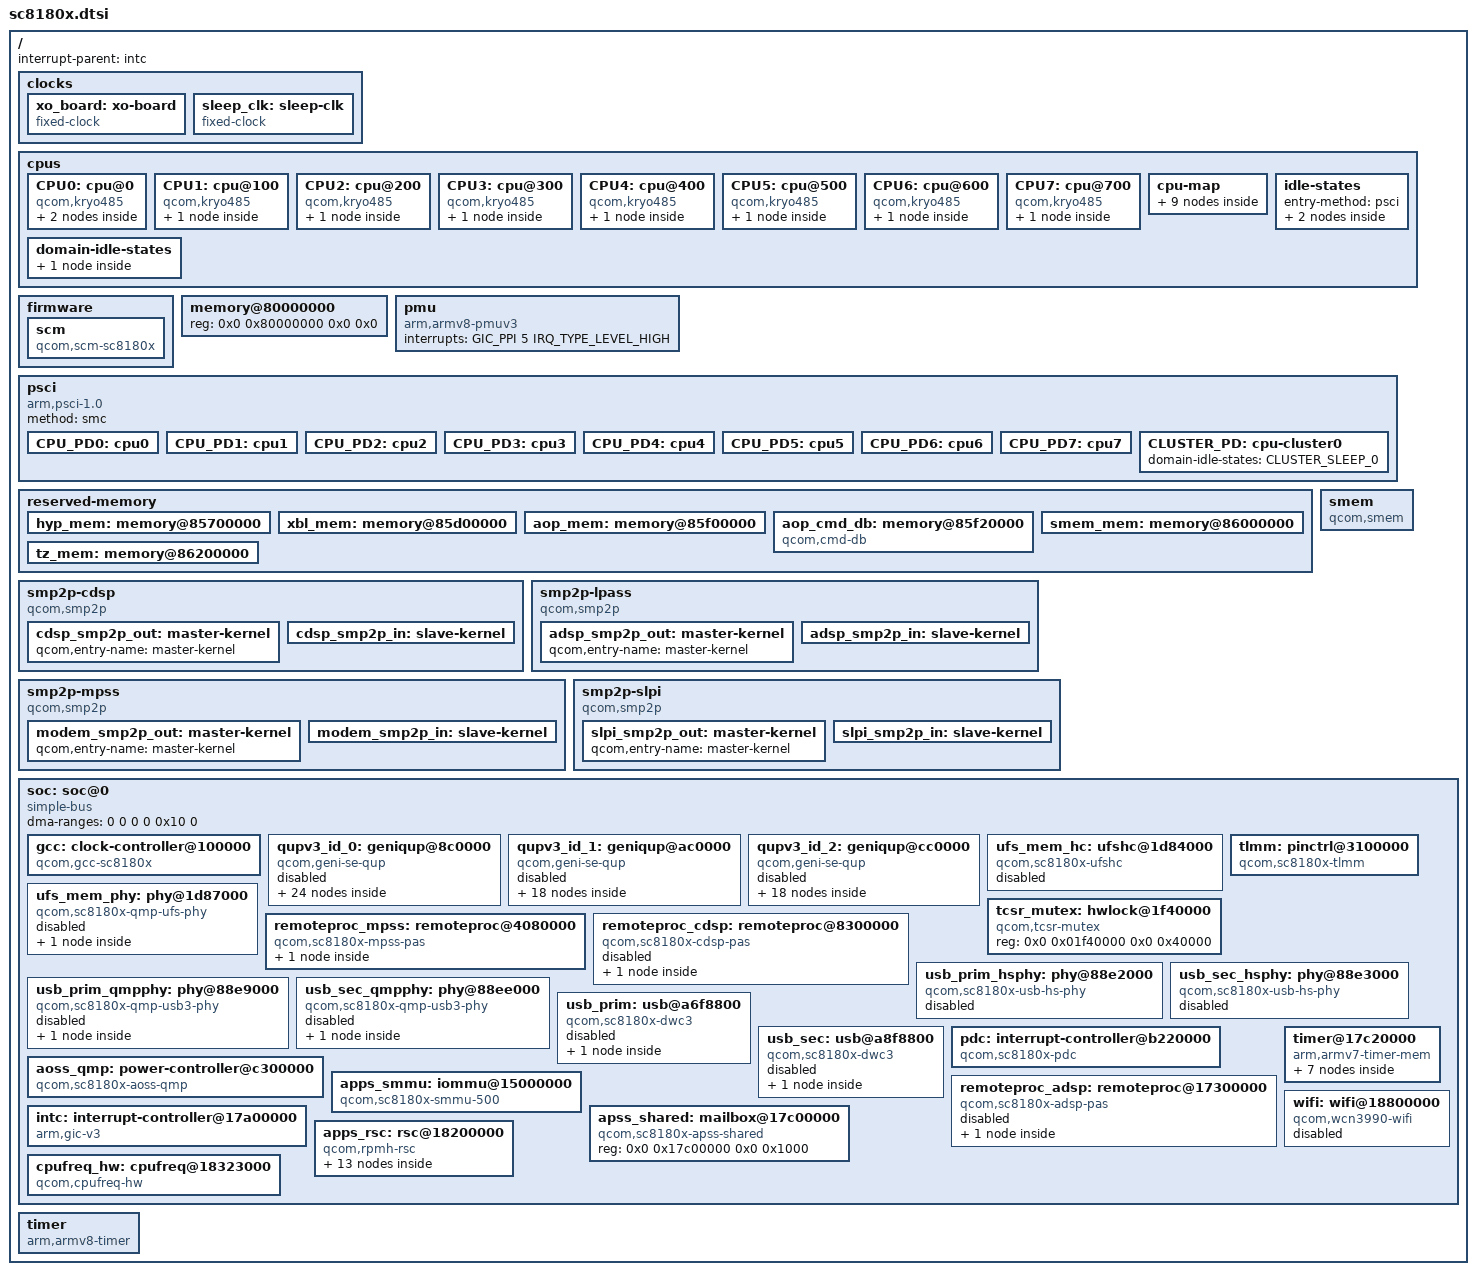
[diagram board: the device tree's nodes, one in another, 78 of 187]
// SPDX-License-Identifier: BSD-3-Clause
/*
 * Copyright (c) 2017-2019, The Linux Foundation. All rights reserved.
 * Copyright (c) 2020-2021, Linaro Limited
 */

#include <dt-bindings/interrupt-controller/arm-gic.h>
#include <dt-bindings/power/qcom-aoss-qmp.h>
#include <dt-bindings/power/qcom-rpmpd.h>
#include <dt-bindings/soc/qcom,rpmh-rsc.h>
#include <dt-bindings/clock/qcom,rpmh.h>
#include <dt-bindings/clock/qcom,gcc-sc8180x.h>
#include <dt-bindings/thermal/thermal.h>

/ {
	interrupt-parent = <&intc>;

	#address-cells = <2>;
	#size-cells = <2>;

	clocks {
		xo_board: xo-board {
			compatible = "fixed-clock";
			#clock-cells = <0>;
			clock-frequency = <38400000>;
			clock-output-names = "xo_board";
		};

		sleep_clk: sleep-clk {
			compatible = "fixed-clock";
			#clock-cells = <0>;
			clock-frequency = <32764>;
			clock-output-names = "sleep_clk";
		};
	};

	cpus {
		#address-cells = <2>;
		#size-cells = <0>;

		CPU0: cpu@0 {
			device_type = "cpu";
			compatible = "qcom,kryo485";
			reg = <0x0 0x0>;
			enable-method = "psci";
			capacity-dmips-mhz = <602>;
			next-level-cache = <&L2_0>;
			qcom,freq-domain = <&cpufreq_hw 0>;
			power-domains = <&CPU_PD0>;
			power-domain-names = "psci";
			#cooling-cells = <2>;
			L2_0: l2-cache {
				compatible = "cache";
				next-level-cache = <&L3_0>;
				L3_0: l3-cache {
				      compatible = "cache";
				};
			};
		};

		CPU1: cpu@100 {
			device_type = "cpu";
			compatible = "qcom,kryo485";
			reg = <0x0 0x100>;
			enable-method = "psci";
			capacity-dmips-mhz = <602>;
			next-level-cache = <&L2_100>;
			qcom,freq-domain = <&cpufreq_hw 0>;
			power-domains = <&CPU_PD1>;
			power-domain-names = "psci";
			#cooling-cells = <2>;
			L2_100: l2-cache {
				compatible = "cache";
				next-level-cache = <&L3_0>;
			};

		};

		CPU2: cpu@200 {
			device_type = "cpu";
			compatible = "qcom,kryo485";
			reg = <0x0 0x200>;
			enable-method = "psci";
			capacity-dmips-mhz = <602>;
			next-level-cache = <&L2_200>;
			qcom,freq-domain = <&cpufreq_hw 0>;
			power-domains = <&CPU_PD2>;
			power-domain-names = "psci";
			#cooling-cells = <2>;
			L2_200: l2-cache {
				compatible = "cache";
				next-level-cache = <&L3_0>;
			};
		};

		CPU3: cpu@300 {
			device_type = "cpu";
			compatible = "qcom,kryo485";
			reg = <0x0 0x300>;
			enable-method = "psci";
			capacity-dmips-mhz = <602>;
			next-level-cache = <&L2_300>;
			qcom,freq-domain = <&cpufreq_hw 0>;
			power-domains = <&CPU_PD3>;
			power-domain-names = "psci";
			#cooling-cells = <2>;
			L2_300: l2-cache {
				compatible = "cache";
				next-level-cache = <&L3_0>;
			};
		};

		CPU4: cpu@400 {
			device_type = "cpu";
			compatible = "qcom,kryo485";
			reg = <0x0 0x400>;
			enable-method = "psci";
			capacity-dmips-mhz = <1024>;
			next-level-cache = <&L2_400>;
			qcom,freq-domain = <&cpufreq_hw 1>;
			power-domains = <&CPU_PD4>;
			power-domain-names = "psci";
			#cooling-cells = <2>;
			L2_400: l2-cache {
				compatible = "cache";
				next-level-cache = <&L3_0>;
			};
		};

		CPU5: cpu@500 {
			device_type = "cpu";
			compatible = "qcom,kryo485";
			reg = <0x0 0x500>;
			enable-method = "psci";
			capacity-dmips-mhz = <1024>;
			next-level-cache = <&L2_500>;
			qcom,freq-domain = <&cpufreq_hw 1>;
			power-domains = <&CPU_PD5>;
			power-domain-names = "psci";
			#cooling-cells = <2>;
			L2_500: l2-cache {
				compatible = "cache";
				next-level-cache = <&L3_0>;
			};
		};

		CPU6: cpu@600 {
			device_type = "cpu";
			compatible = "qcom,kryo485";
			reg = <0x0 0x600>;
			enable-method = "psci";
			capacity-dmips-mhz = <1024>;
			next-level-cache = <&L2_600>;
			qcom,freq-domain = <&cpufreq_hw 1>;
			power-domains = <&CPU_PD6>;
			power-domain-names = "psci";
			#cooling-cells = <2>;
			L2_600: l2-cache {
				compatible = "cache";
				next-level-cache = <&L3_0>;
			};
		};

		CPU7: cpu@700 {
			device_type = "cpu";
			compatible = "qcom,kryo485";
			reg = <0x0 0x700>;
			enable-method = "psci";
			capacity-dmips-mhz = <1024>;
			next-level-cache = <&L2_700>;
			qcom,freq-domain = <&cpufreq_hw 1>;
			power-domains = <&CPU_PD7>;
			power-domain-names = "psci";
			#cooling-cells = <2>;
			L2_700: l2-cache {
				compatible = "cache";
				next-level-cache = <&L3_0>;
			};
		};

		cpu-map {
			cluster0 {
				core0 {
					cpu = <&CPU0>;
				};

				core1 {
					cpu = <&CPU1>;
				};

				core2 {
					cpu = <&CPU2>;
				};

				core3 {
					cpu = <&CPU3>;
				};

				core4 {
					cpu = <&CPU4>;
				};

				core5 {
					cpu = <&CPU5>;
				};

				core6 {
					cpu = <&CPU6>;
				};

				core7 {
					cpu = <&CPU7>;
				};
			};
		};

		idle-states {
			entry-method = "psci";

			LITTLE_CPU_SLEEP_0: cpu-sleep-0-0 {
				compatible = "arm,idle-state";
				idle-state-name = "little-rail-power-collapse";
				arm,psci-suspend-param = <0x40000004>;
				entry-latency-us = <355>;
				exit-latency-us = <909>;
				min-residency-us = <3934>;
				local-timer-stop;
			};

			BIG_CPU_SLEEP_0: cpu-sleep-1-0 {
				compatible = "arm,idle-state";
				idle-state-name = "big-rail-power-collapse";
				arm,psci-suspend-param = <0x40000004>;
				entry-latency-us = <241>;
				exit-latency-us = <1461>;
				min-residency-us = <4488>;
				local-timer-stop;
			};
		};

		domain-idle-states {
			CLUSTER_SLEEP_0: cluster-sleep-0 {
				compatible = "domain-idle-state";
				idle-state-name = "cluster-power-collapse";
				arm,psci-suspend-param = <0x4100c244>;
				entry-latency-us = <3263>;
				exit-latency-us = <6562>;
				min-residency-us = <9987>;
			};
		};
	};

	firmware {
		scm: scm {
			compatible = "qcom,scm-sc8180x", "qcom,scm";
		};
	};

	memory@80000000 {
		device_type = "memory";
		/* We expect the bootloader to fill in the size */
		reg = <0x0 0x80000000 0x0 0x0>;
	};

	pmu {
		compatible = "arm,armv8-pmuv3";
		interrupts = <GIC_PPI 5 IRQ_TYPE_LEVEL_HIGH>;
	};

	psci {
		compatible = "arm,psci-1.0";
		method = "smc";

		CPU_PD0: cpu0 {
			#power-domain-cells = <0>;
			power-domains = <&CLUSTER_PD>;
			domain-idle-states = <&LITTLE_CPU_SLEEP_0>;
		};

		CPU_PD1: cpu1 {
			#power-domain-cells = <0>;
			power-domains = <&CLUSTER_PD>;
			domain-idle-states = <&LITTLE_CPU_SLEEP_0>;
		};

		CPU_PD2: cpu2 {
			#power-domain-cells = <0>;
			power-domains = <&CLUSTER_PD>;
			domain-idle-states = <&LITTLE_CPU_SLEEP_0>;
		};

		CPU_PD3: cpu3 {
			#power-domain-cells = <0>;
			power-domains = <&CLUSTER_PD>;
			domain-idle-states = <&LITTLE_CPU_SLEEP_0>;
		};

		CPU_PD4: cpu4 {
			#power-domain-cells = <0>;
			power-domains = <&CLUSTER_PD>;
			domain-idle-states = <&BIG_CPU_SLEEP_0>;
		};

		CPU_PD5: cpu5 {
			#power-domain-cells = <0>;
			power-domains = <&CLUSTER_PD>;
			domain-idle-states = <&BIG_CPU_SLEEP_0>;
		};

		CPU_PD6: cpu6 {
			#power-domain-cells = <0>;
			power-domains = <&CLUSTER_PD>;
			domain-idle-states = <&BIG_CPU_SLEEP_0>;
		};

		CPU_PD7: cpu7 {
			#power-domain-cells = <0>;
			power-domains = <&CLUSTER_PD>;
			domain-idle-states = <&BIG_CPU_SLEEP_0>;
		};

		CLUSTER_PD: cpu-cluster0 {
			#power-domain-cells = <0>;
			domain-idle-states = <&CLUSTER_SLEEP_0>;
		};
	};

	reserved-memory {
		#address-cells = <2>;
		#size-cells = <2>;
		ranges;

		hyp_mem: memory@85700000 {
			reg = <0x0 0x85700000 0x0 0x600000>;
			no-map;
		};

		xbl_mem: memory@85d00000 {
			reg = <0x0 0x85d00000 0x0 0x140000>;
			no-map;
		};

		aop_mem: memory@85f00000 {
			reg = <0x0 0x85f00000 0x0 0x20000>;
			no-map;
		};

		aop_cmd_db: memory@85f20000 {
			compatible = "qcom,cmd-db";
			reg = <0x0 0x85f20000 0x0 0x20000>;
			no-map;
		};

		smem_mem: memory@86000000 {
			reg = <0x0 0x86000000 0x0 0x200000>;
			no-map;
		};

		tz_mem: memory@86200000 {
			reg = <0x0 0x86200000 0x0 0x3900000>;
			no-map;
		};
	};

	smem {
		compatible = "qcom,smem";
		memory-region = <&smem_mem>;
		hwlocks = <&tcsr_mutex 3>;
	};

	smp2p-cdsp {
		compatible = "qcom,smp2p";
		qcom,smem = <94>, <432>;

		interrupts = <GIC_SPI 576 IRQ_TYPE_EDGE_RISING>;

		mboxes = <&apss_shared 6>;

		qcom,local-pid = <0>;
		qcom,remote-pid = <5>;

		cdsp_smp2p_out: master-kernel {
			qcom,entry-name = "master-kernel";
			#qcom,smem-state-cells = <1>;
		};

		cdsp_smp2p_in: slave-kernel {
			qcom,entry-name = "slave-kernel";

			interrupt-controller;
			#interrupt-cells = <2>;
		};
	};

	smp2p-lpass {
		compatible = "qcom,smp2p";
		qcom,smem = <443>, <429>;

		interrupts = <GIC_SPI 158 IRQ_TYPE_EDGE_RISING>;

		mboxes = <&apss_shared 10>;

		qcom,local-pid = <0>;
		qcom,remote-pid = <2>;

		adsp_smp2p_out: master-kernel {
			qcom,entry-name = "master-kernel";
			#qcom,smem-state-cells = <1>;
		};

		adsp_smp2p_in: slave-kernel {
			qcom,entry-name = "slave-kernel";

			interrupt-controller;
			#interrupt-cells = <2>;
		};
	};

	smp2p-mpss {
		compatible = "qcom,smp2p";
		qcom,smem = <435>, <428>;

		interrupts = <GIC_SPI 451 IRQ_TYPE_EDGE_RISING>;

		mboxes = <&apss_shared 14>;

		qcom,local-pid = <0>;
		qcom,remote-pid = <1>;

		modem_smp2p_out: master-kernel {
			qcom,entry-name = "master-kernel";
			#qcom,smem-state-cells = <1>;
		};

		modem_smp2p_in: slave-kernel {
			qcom,entry-name = "slave-kernel";

			interrupt-controller;
			#interrupt-cells = <2>;
		};
	};

	smp2p-slpi {
		compatible = "qcom,smp2p";
		qcom,smem = <481>, <430>;

		interrupts = <GIC_SPI 172 IRQ_TYPE_EDGE_RISING>;

		mboxes = <&apss_shared 26>;

		qcom,local-pid = <0>;
		qcom,remote-pid = <3>;

		slpi_smp2p_out: master-kernel {
			qcom,entry-name = "master-kernel";
			#qcom,smem-state-cells = <1>;
		};

		slpi_smp2p_in: slave-kernel {
			qcom,entry-name = "slave-kernel";

			interrupt-controller;
			#interrupt-cells = <2>;
		};
	};

	soc: soc@0 {
		#address-cells = <2>;
		#size-cells = <2>;
		ranges = <0 0 0 0 0x10 0>;
		dma-ranges = <0 0 0 0 0x10 0>;
		compatible = "simple-bus";

		gcc: clock-controller@100000 {
			compatible = "qcom,gcc-sc8180x";
			reg = <0x0 0x00100000 0x0 0x1f0000>;
			#clock-cells = <1>;
			#reset-cells = <1>;
			#power-domain-cells = <1>;
			clock-names = "bi_tcxo",
				      "sleep_clk";
			clocks = <&rpmhcc RPMH_CXO_CLK>,
				 <&sleep_clk>;
		};

		qupv3_id_0: geniqup@8c0000 {
			compatible = "qcom,geni-se-qup";
			reg = <0 0x008c0000 0 0x6000>;
			clock-names = "m-ahb", "s-ahb";
			clocks = <&gcc GCC_QUPV3_WRAP_0_M_AHB_CLK>,
				 <&gcc GCC_QUPV3_WRAP_0_S_AHB_CLK>;
			#address-cells = <2>;
			#size-cells = <2>;
			ranges;
			iommus = <&apps_smmu 0x4c3 0>;
			status = "disabled";

			i2c0: i2c@880000 {
				compatible = "qcom,geni-i2c";
				reg = <0 0x00880000 0 0x4000>;
				clock-names = "se";
				clocks = <&gcc GCC_QUPV3_WRAP0_S0_CLK>;
				interrupts = <GIC_SPI 601 IRQ_TYPE_LEVEL_HIGH>;
				#address-cells = <1>;
				#size-cells = <0>;
				status = "disabled";
			};

			spi0: spi@880000 {
				compatible = "qcom,geni-spi";
				reg = <0 0x00880000 0 0x4000>;
				clock-names = "se";
				clocks = <&gcc GCC_QUPV3_WRAP0_S0_CLK>;
				interrupts = <GIC_SPI 601 IRQ_TYPE_LEVEL_HIGH>;
				#address-cells = <1>;
				#size-cells = <0>;
				status = "disabled";
			};

			uart0: serial@880000 {
				compatible = "qcom,geni-uart";
				reg = <0 0x00880000 0 0x4000>;
				clock-names = "se";
				clocks = <&gcc GCC_QUPV3_WRAP0_S0_CLK>;
				interrupts = <GIC_SPI 601 IRQ_TYPE_LEVEL_HIGH>;
				status = "disabled";
			};

			i2c1: i2c@884000 {
				compatible = "qcom,geni-i2c";
				reg = <0 0x00884000 0 0x4000>;
				clock-names = "se";
				clocks = <&gcc GCC_QUPV3_WRAP0_S1_CLK>;
				interrupts = <GIC_SPI 602 IRQ_TYPE_LEVEL_HIGH>;
				#address-cells = <1>;
				#size-cells = <0>;
				status = "disabled";
			};

			spi1: spi@884000 {
				compatible = "qcom,geni-spi";
				reg = <0 0x00884000 0 0x4000>;
				clock-names = "se";
				clocks = <&gcc GCC_QUPV3_WRAP0_S1_CLK>;
				interrupts = <GIC_SPI 602 IRQ_TYPE_LEVEL_HIGH>;
				#address-cells = <1>;
				#size-cells = <0>;
				status = "disabled";
			};

			uart1: serial@884000 {
				compatible = "qcom,geni-uart";
				reg = <0 0x00884000 0 0x4000>;
				clock-names = "se";
				clocks = <&gcc GCC_QUPV3_WRAP0_S1_CLK>;
				interrupts = <GIC_SPI 602 IRQ_TYPE_LEVEL_HIGH>;
				status = "disabled";
			};

			i2c2: i2c@888000 {
				compatible = "qcom,geni-i2c";
				reg = <0 0x00888000 0 0x4000>;
				clock-names = "se";
				clocks = <&gcc GCC_QUPV3_WRAP0_S2_CLK>;
				interrupts = <GIC_SPI 603 IRQ_TYPE_LEVEL_HIGH>;
				#address-cells = <1>;
				#size-cells = <0>;
				status = "disabled";
			};

			spi2: spi@888000 {
				compatible = "qcom,geni-spi";
				reg = <0 0x00888000 0 0x4000>;
				clock-names = "se";
				clocks = <&gcc GCC_QUPV3_WRAP0_S2_CLK>;
				interrupts = <GIC_SPI 603 IRQ_TYPE_LEVEL_HIGH>;
				#address-cells = <1>;
				#size-cells = <0>;
				status = "disabled";
			};

			uart2: serial@888000 {
				compatible = "qcom,geni-uart";
				reg = <0 0x00888000 0 0x4000>;
				clock-names = "se";
				clocks = <&gcc GCC_QUPV3_WRAP0_S2_CLK>;
				interrupts = <GIC_SPI 603 IRQ_TYPE_LEVEL_HIGH>;
				status = "disabled";
			};

			i2c3: i2c@88c000 {
				compatible = "qcom,geni-i2c";
				reg = <0 0x0088c000 0 0x4000>;
				clock-names = "se";
				clocks = <&gcc GCC_QUPV3_WRAP0_S3_CLK>;
				interrupts = <GIC_SPI 604 IRQ_TYPE_LEVEL_HIGH>;
				#address-cells = <1>;
				#size-cells = <0>;
				status = "disabled";
			};

			spi3: spi@88c000 {
				compatible = "qcom,geni-spi";
				reg = <0 0x0088c000 0 0x4000>;
				clock-names = "se";
				clocks = <&gcc GCC_QUPV3_WRAP0_S3_CLK>;
				interrupts = <GIC_SPI 604 IRQ_TYPE_LEVEL_HIGH>;
				#address-cells = <1>;
				#size-cells = <0>;
				status = "disabled";
			};

			uart3: serial@88c000 {
				compatible = "qcom,geni-uart";
				reg = <0 0x0088c000 0 0x4000>;
				clock-names = "se";
				clocks = <&gcc GCC_QUPV3_WRAP0_S3_CLK>;
				interrupts = <GIC_SPI 604 IRQ_TYPE_LEVEL_HIGH>;
				status = "disabled";
			};

			i2c4: i2c@890000 {
				compatible = "qcom,geni-i2c";
				reg = <0 0x00890000 0 0x4000>;
				clock-names = "se";
				clocks = <&gcc GCC_QUPV3_WRAP0_S4_CLK>;
				interrupts = <GIC_SPI 605 IRQ_TYPE_LEVEL_HIGH>;
				#address-cells = <1>;
				#size-cells = <0>;
				status = "disabled";
			};

			spi4: spi@890000 {
				compatible = "qcom,geni-spi";
				reg = <0 0x00890000 0 0x4000>;
				clock-names = "se";
				clocks = <&gcc GCC_QUPV3_WRAP0_S4_CLK>;
				interrupts = <GIC_SPI 605 IRQ_TYPE_LEVEL_HIGH>;
				#address-cells = <1>;
				#size-cells = <0>;
				status = "disabled";
			};

			uart4: serial@890000 {
				compatible = "qcom,geni-uart";
				reg = <0 0x00890000 0 0x4000>;
				clock-names = "se";
				clocks = <&gcc GCC_QUPV3_WRAP0_S4_CLK>;
				interrupts = <GIC_SPI 605 IRQ_TYPE_LEVEL_HIGH>;
				status = "disabled";
			};

			i2c5: i2c@894000 {
				compatible = "qcom,geni-i2c";
				reg = <0 0x00894000 0 0x4000>;
				clock-names = "se";
				clocks = <&gcc GCC_QUPV3_WRAP0_S5_CLK>;
				interrupts = <GIC_SPI 606 IRQ_TYPE_LEVEL_HIGH>;
				#address-cells = <1>;
				#size-cells = <0>;
				status = "disabled";
			};

			spi5: spi@894000 {
				compatible = "qcom,geni-spi";
				reg = <0 0x00894000 0 0x4000>;
				clock-names = "se";
				clocks = <&gcc GCC_QUPV3_WRAP0_S5_CLK>;
				interrupts = <GIC_SPI 606 IRQ_TYPE_LEVEL_HIGH>;
				#address-cells = <1>;
				#size-cells = <0>;
				status = "disabled";
			};

			uart5: serial@894000 {
				compatible = "qcom,geni-uart";
				reg = <0 0x00894000 0 0x4000>;
				clock-names = "se";
				clocks = <&gcc GCC_QUPV3_WRAP0_S5_CLK>;
				interrupts = <GIC_SPI 606 IRQ_TYPE_LEVEL_HIGH>;
				status = "disabled";
			};

			i2c6: i2c@898000 {
				compatible = "qcom,geni-i2c";
				reg = <0 0x00898000 0 0x4000>;
				clock-names = "se";
				clocks = <&gcc GCC_QUPV3_WRAP0_S6_CLK>;
				interrupts = <GIC_SPI 607 IRQ_TYPE_LEVEL_HIGH>;
				#address-cells = <1>;
				#size-cells = <0>;
				status = "disabled";
			};

			spi6: spi@898000 {
				compatible = "qcom,geni-spi";
				reg = <0 0x00898000 0 0x4000>;
				clock-names = "se";
				clocks = <&gcc GCC_QUPV3_WRAP0_S6_CLK>;
				interrupts = <GIC_SPI 607 IRQ_TYPE_LEVEL_HIGH>;
				#address-cells = <1>;
				#size-cells = <0>;
				status = "disabled";
			};

			uart6: serial@898000 {
				compatible = "qcom,geni-uart";
				reg = <0 0x00898000 0 0x4000>;
				clock-names = "se";
				clocks = <&gcc GCC_QUPV3_WRAP0_S6_CLK>;
				interrupts = <GIC_SPI 607 IRQ_TYPE_LEVEL_HIGH>;
				status = "disabled";
			};

			i2c7: i2c@89c000 {
				compatible = "qcom,geni-i2c";
				reg = <0 0x0089c000 0 0x4000>;
				clock-names = "se";
				clocks = <&gcc GCC_QUPV3_WRAP0_S7_CLK>;
				interrupts = <GIC_SPI 608 IRQ_TYPE_LEVEL_HIGH>;
				#address-cells = <1>;
				#size-cells = <0>;
				status = "disabled";
			};

			spi7: spi@89c000 {
				compatible = "qcom,geni-spi";
				reg = <0 0x0089c000 0 0x4000>;
				clock-names = "se";
				clocks = <&gcc GCC_QUPV3_WRAP0_S7_CLK>;
				interrupts = <GIC_SPI 608 IRQ_TYPE_LEVEL_HIGH>;
				#address-cells = <1>;
				#size-cells = <0>;
				status = "disabled";
			};

			uart7: serial@89c000 {
				compatible = "qcom,geni-uart";
				reg = <0 0x0089c000 0 0x4000>;
				clock-names = "se";
				clocks = <&gcc GCC_QUPV3_WRAP0_S7_CLK>;
				interrupts = <GIC_SPI 608 IRQ_TYPE_LEVEL_HIGH>;
				status = "disabled";
			};
		};

		qupv3_id_1: geniqup@ac0000 {
			compatible = "qcom,geni-se-qup";
			reg = <0x0 0x00ac0000 0x0 0x6000>;
			clock-names = "m-ahb", "s-ahb";
			clocks = <&gcc GCC_QUPV3_WRAP_1_M_AHB_CLK>,
				 <&gcc GCC_QUPV3_WRAP_1_S_AHB_CLK>;
			#address-cells = <2>;
			#size-cells = <2>;
			ranges;
			iommus = <&apps_smmu 0x603 0>;
			status = "disabled";

			i2c8: i2c@a80000 {
				compatible = "qcom,geni-i2c";
				reg = <0 0x00a80000 0 0x4000>;
				clock-names = "se";
				clocks = <&gcc GCC_QUPV3_WRAP1_S0_CLK>;
				interrupts = <GIC_SPI 353 IRQ_TYPE_LEVEL_HIGH>;
				#address-cells = <1>;
				#size-cells = <0>;
				status = "disabled";
			};

			spi8: spi@a80000 {
				compatible = "qcom,geni-spi";
				reg = <0 0x00a80000 0 0x4000>;
				clock-names = "se";
				clocks = <&gcc GCC_QUPV3_WRAP1_S0_CLK>;
				interrupts = <GIC_SPI 353 IRQ_TYPE_LEVEL_HIGH>;
				#address-cells = <1>;
				#size-cells = <0>;
				status = "disabled";
			};

			uart8: serial@a80000 {
				compatible = "qcom,geni-uart";
				reg = <0 0x00a80000 0 0x4000>;
				clock-names = "se";
				clocks = <&gcc GCC_QUPV3_WRAP1_S0_CLK>;
				interrupts = <GIC_SPI 353 IRQ_TYPE_LEVEL_HIGH>;
				status = "disabled";
			};

			i2c9: i2c@a84000 {
				compatible = "qcom,geni-i2c";
				reg = <0 0x00a84000 0 0x4000>;
				clock-names = "se";
				clocks = <&gcc GCC_QUPV3_WRAP1_S1_CLK>;
				interrupts = <GIC_SPI 354 IRQ_TYPE_LEVEL_HIGH>;
				#address-cells = <1>;
				#size-cells = <0>;
				status = "disabled";
			};

			spi9: spi@a84000 {
				compatible = "qcom,geni-spi";
				reg = <0 0x00a84000 0 0x4000>;
				clock-names = "se";
				clocks = <&gcc GCC_QUPV3_WRAP1_S1_CLK>;
				interrupts = <GIC_SPI 354 IRQ_TYPE_LEVEL_HIGH>;
				#address-cells = <1>;
				#size-cells = <0>;
				status = "disabled";
			};

			uart9: serial@a84000 {
				compatible = "qcom,geni-debug-uart";
				reg = <0 0x00a84000 0 0x4000>;
				clock-names = "se";
				clocks = <&gcc GCC_QUPV3_WRAP1_S1_CLK>;
				interrupts = <GIC_SPI 354 IRQ_TYPE_LEVEL_HIGH>;
				status = "disabled";
			};

			i2c10: i2c@a88000 {
				compatible = "qcom,geni-i2c";
				reg = <0 0x00a88000 0 0x4000>;
				clock-names = "se";
				clocks = <&gcc GCC_QUPV3_WRAP1_S2_CLK>;
				interrupts = <GIC_SPI 355 IRQ_TYPE_LEVEL_HIGH>;
				#address-cells = <1>;
				#size-cells = <0>;
				status = "disabled";
			};

			spi10: spi@a88000 {
				compatible = "qcom,geni-spi";
				reg = <0 0x00a88000 0 0x4000>;
				clock-names = "se";
				clocks = <&gcc GCC_QUPV3_WRAP1_S2_CLK>;
				interrupts = <GIC_SPI 355 IRQ_TYPE_LEVEL_HIGH>;
				#address-cells = <1>;
				#size-cells = <0>;
				status = "disabled";
			};

			uart10: serial@a88000 {
				compatible = "qcom,geni-uart";
				reg = <0 0x00a88000 0 0x4000>;
				clock-names = "se";
				clocks = <&gcc GCC_QUPV3_WRAP1_S2_CLK>;
				interrupts = <GIC_SPI 355 IRQ_TYPE_LEVEL_HIGH>;
				status = "disabled";
			};

			i2c11: i2c@a8c000 {
				compatible = "qcom,geni-i2c";
				reg = <0 0x00a8c000 0 0x4000>;
				clock-names = "se";
				clocks = <&gcc GCC_QUPV3_WRAP1_S3_CLK>;
				interrupts = <GIC_SPI 356 IRQ_TYPE_LEVEL_HIGH>;
				#address-cells = <1>;
				#size-cells = <0>;
				status = "disabled";
			};

			spi11: spi@a8c000 {
				compatible = "qcom,geni-spi";
				reg = <0 0x00a8c000 0 0x4000>;
				clock-names = "se";
				clocks = <&gcc GCC_QUPV3_WRAP1_S3_CLK>;
				interrupts = <GIC_SPI 356 IRQ_TYPE_LEVEL_HIGH>;
				#address-cells = <1>;
				#size-cells = <0>;
				status = "disabled";
			};

			uart11: serial@a8c000 {
				compatible = "qcom,geni-uart";
				reg = <0 0x00a8c000 0 0x4000>;
				clock-names = "se";
				clocks = <&gcc GCC_QUPV3_WRAP1_S3_CLK>;
				interrupts = <GIC_SPI 356 IRQ_TYPE_LEVEL_HIGH>;
				status = "disabled";
			};

			i2c12: i2c@a90000 {
				compatible = "qcom,geni-i2c";
				reg = <0 0x00a90000 0 0x4000>;
				clock-names = "se";
				clocks = <&gcc GCC_QUPV3_WRAP1_S4_CLK>;
				interrupts = <GIC_SPI 357 IRQ_TYPE_LEVEL_HIGH>;
				#address-cells = <1>;
				#size-cells = <0>;
				status = "disabled";
			};

			spi12: spi@a90000 {
				compatible = "qcom,geni-spi";
				reg = <0 0x00a90000 0 0x4000>;
				clock-names = "se";
				clocks = <&gcc GCC_QUPV3_WRAP1_S4_CLK>;
				interrupts = <GIC_SPI 357 IRQ_TYPE_LEVEL_HIGH>;
				#address-cells = <1>;
				#size-cells = <0>;
				status = "disabled";
			};

			uart12: serial@a90000 {
				compatible = "qcom,geni-uart";
				reg = <0 0x00a90000 0 0x4000>;
				clock-names = "se";
				clocks = <&gcc GCC_QUPV3_WRAP1_S4_CLK>;
				interrupts = <GIC_SPI 357 IRQ_TYPE_LEVEL_HIGH>;
				status = "disabled";
			};

			i2c16: i2c@a94000 {
				compatible = "qcom,geni-i2c";
				reg = <0 0x00a94000 0 0x4000>;
				clock-names = "se";
				clocks = <&gcc GCC_QUPV3_WRAP1_S5_CLK>;
				interrupts = <GIC_SPI 358 IRQ_TYPE_LEVEL_HIGH>;
				#address-cells = <1>;
				#size-cells = <0>;
				status = "disabled";
			};

			spi16: spi@a94000 {
				compatible = "qcom,geni-spi";
				reg = <0 0x00a94000 0 0x4000>;
				clock-names = "se";
				clocks = <&gcc GCC_QUPV3_WRAP1_S5_CLK>;
				interrupts = <GIC_SPI 358 IRQ_TYPE_LEVEL_HIGH>;
				#address-cells = <1>;
				#size-cells = <0>;
				status = "disabled";
			};

			uart16: serial@a94000 {
				compatible = "qcom,geni-uart";
				reg = <0 0x00a94000 0 0x4000>;
				clock-names = "se";
				clocks = <&gcc GCC_QUPV3_WRAP1_S5_CLK>;
				interrupts = <GIC_SPI 358 IRQ_TYPE_LEVEL_HIGH>;
				status = "disabled";
			};
		};

		qupv3_id_2: geniqup@cc0000 {
			compatible = "qcom,geni-se-qup";
			reg = <0x0 0x00cc0000 0x0 0x6000>;
			clock-names = "m-ahb", "s-ahb";
			clocks = <&gcc GCC_QUPV3_WRAP_2_M_AHB_CLK>,
				 <&gcc GCC_QUPV3_WRAP_2_S_AHB_CLK>;
			#address-cells = <2>;
			#size-cells = <2>;
			ranges;
			iommus = <&apps_smmu 0x7a3 0>;
			status = "disabled";

			i2c17: i2c@c80000 {
				compatible = "qcom,geni-i2c";
				reg = <0 0x00c80000 0 0x4000>;
				clock-names = "se";
				clocks = <&gcc GCC_QUPV3_WRAP2_S0_CLK>;
				interrupts = <GIC_SPI 373 IRQ_TYPE_LEVEL_HIGH>;
				#address-cells = <1>;
				#size-cells = <0>;
				status = "disabled";
			};

			spi17: spi@c80000 {
				compatible = "qcom,geni-spi";
				reg = <0 0x00c80000 0 0x4000>;
				clock-names = "se";
				clocks = <&gcc GCC_QUPV3_WRAP2_S0_CLK>;
				interrupts = <GIC_SPI 373 IRQ_TYPE_LEVEL_HIGH>;
				#address-cells = <1>;
				#size-cells = <0>;
				status = "disabled";
			};

			uart17: serial@c80000 {
				compatible = "qcom,geni-uart";
				reg = <0 0x00c80000 0 0x4000>;
				clock-names = "se";
				clocks = <&gcc GCC_QUPV3_WRAP2_S0_CLK>;
				interrupts = <GIC_SPI 373 IRQ_TYPE_LEVEL_HIGH>;
				status = "disabled";
			};

			i2c18: i2c@c84000 {
				compatible = "qcom,geni-i2c";
				reg = <0 0x00c84000 0 0x4000>;
				clock-names = "se";
				clocks = <&gcc GCC_QUPV3_WRAP2_S1_CLK>;
				interrupts = <GIC_SPI 583 IRQ_TYPE_LEVEL_HIGH>;
				#address-cells = <1>;
				#size-cells = <0>;
				status = "disabled";
			};

			spi18: spi@c84000 {
				compatible = "qcom,geni-spi";
				reg = <0 0x00c84000 0 0x4000>;
				clock-names = "se";
				clocks = <&gcc GCC_QUPV3_WRAP2_S1_CLK>;
				interrupts = <GIC_SPI 583 IRQ_TYPE_LEVEL_HIGH>;
				#address-cells = <1>;
				#size-cells = <0>;
				status = "disabled";
			};

			uart18: serial@c84000 {
				compatible = "qcom,geni-uart";
				reg = <0 0x00c84000 0 0x4000>;
				clock-names = "se";
				clocks = <&gcc GCC_QUPV3_WRAP2_S1_CLK>;
				interrupts = <GIC_SPI 583 IRQ_TYPE_LEVEL_HIGH>;
				status = "disabled";
			};

			i2c19: i2c@c88000 {
				compatible = "qcom,geni-i2c";
				reg = <0 0x00c88000 0 0x4000>;
				clock-names = "se";
				clocks = <&gcc GCC_QUPV3_WRAP2_S2_CLK>;
				interrupts = <GIC_SPI 584 IRQ_TYPE_LEVEL_HIGH>;
				#address-cells = <1>;
				#size-cells = <0>;
				status = "disabled";
			};

			spi19: spi@c88000 {
				compatible = "qcom,geni-spi";
				reg = <0 0x00c88000 0 0x4000>;
				clock-names = "se";
				clocks = <&gcc GCC_QUPV3_WRAP2_S2_CLK>;
				interrupts = <GIC_SPI 584 IRQ_TYPE_LEVEL_HIGH>;
				#address-cells = <1>;
				#size-cells = <0>;
				status = "disabled";
			};

			uart19: serial@c88000 {
				compatible = "qcom,geni-uart";
				reg = <0 0x00c88000 0 0x4000>;
				clock-names = "se";
				clocks = <&gcc GCC_QUPV3_WRAP2_S2_CLK>;
				interrupts = <GIC_SPI 584 IRQ_TYPE_LEVEL_HIGH>;
				status = "disabled";
			};

			i2c13: i2c@c8c000 {
				compatible = "qcom,geni-i2c";
				reg = <0 0x00c8c000 0 0x4000>;
				clock-names = "se";
				clocks = <&gcc GCC_QUPV3_WRAP2_S3_CLK>;
				interrupts = <GIC_SPI 585 IRQ_TYPE_LEVEL_HIGH>;
				#address-cells = <1>;
				#size-cells = <0>;
				status = "disabled";
			};

			spi13: spi@c8c000 {
				compatible = "qcom,geni-spi";
				reg = <0 0x00c8c000 0 0x4000>;
				clock-names = "se";
				clocks = <&gcc GCC_QUPV3_WRAP2_S3_CLK>;
				interrupts = <GIC_SPI 585 IRQ_TYPE_LEVEL_HIGH>;
				#address-cells = <1>;
				#size-cells = <0>;
				status = "disabled";
			};

			uart13: serial@c8c000 {
				compatible = "qcom,geni-uart";
				reg = <0 0x00c8c000 0 0x4000>;
				clock-names = "se";
				clocks = <&gcc GCC_QUPV3_WRAP2_S3_CLK>;
				interrupts = <GIC_SPI 585 IRQ_TYPE_LEVEL_HIGH>;
				status = "disabled";
			};

			i2c14: i2c@c90000 {
				compatible = "qcom,geni-i2c";
				reg = <0 0x00c90000 0 0x4000>;
				clock-names = "se";
				clocks = <&gcc GCC_QUPV3_WRAP2_S4_CLK>;
				interrupts = <GIC_SPI 586 IRQ_TYPE_LEVEL_HIGH>;
				#address-cells = <1>;
				#size-cells = <0>;
				status = "disabled";
			};

			spi14: spi@c90000 {
				compatible = "qcom,geni-spi";
				reg = <0 0x00c90000 0 0x4000>;
				clock-names = "se";
				clocks = <&gcc GCC_QUPV3_WRAP2_S4_CLK>;
				interrupts = <GIC_SPI 586 IRQ_TYPE_LEVEL_HIGH>;
				#address-cells = <1>;
				#size-cells = <0>;
				status = "disabled";
			};

			uart14: serial@c90000 {
				compatible = "qcom,geni-uart";
				reg = <0 0x00c90000 0 0x4000>;
				clock-names = "se";
				clocks = <&gcc GCC_QUPV3_WRAP2_S4_CLK>;
				interrupts = <GIC_SPI 586 IRQ_TYPE_LEVEL_HIGH>;
				status = "disabled";
			};

			i2c15: i2c@c94000 {
				compatible = "qcom,geni-i2c";
				reg = <0 0x00c94000 0 0x4000>;
				clock-names = "se";
				clocks = <&gcc GCC_QUPV3_WRAP2_S5_CLK>;
				interrupts = <GIC_SPI 587 IRQ_TYPE_LEVEL_HIGH>;
				#address-cells = <1>;
				#size-cells = <0>;
				status = "disabled";
			};

			spi15: spi@c94000 {
				compatible = "qcom,geni-spi";
				reg = <0 0x00c94000 0 0x4000>;
				clock-names = "se";
				clocks = <&gcc GCC_QUPV3_WRAP2_S5_CLK>;
				interrupts = <GIC_SPI 587 IRQ_TYPE_LEVEL_HIGH>;
				#address-cells = <1>;
				#size-cells = <0>;
				status = "disabled";
			};

			uart15: serial@c94000 {
				compatible = "qcom,geni-uart";
				reg = <0 0x00c94000 0 0x4000>;
				clock-names = "se";
				clocks = <&gcc GCC_QUPV3_WRAP2_S5_CLK>;
				interrupts = <GIC_SPI 587 IRQ_TYPE_LEVEL_HIGH>;
				status = "disabled";
			};
		};

		ufs_mem_hc: ufshc@1d84000 {
			compatible = "qcom,sc8180x-ufshc", "qcom,ufshc",
				     "jedec,ufs-2.0";
			reg = <0 0x01d84000 0 0x2500>;
			interrupts = <GIC_SPI 265 IRQ_TYPE_LEVEL_HIGH>;
			phys = <&ufs_mem_phy_lanes>;
			phy-names = "ufsphy";
			lanes-per-direction = <2>;
			#reset-cells = <1>;
			resets = <&gcc GCC_UFS_PHY_BCR>;
			reset-names = "rst";

			iommus = <&apps_smmu 0x300 0>;

			clock-names =
				"core_clk",
				"bus_aggr_clk",
				"iface_clk",
				"core_clk_unipro",
				"ref_clk",
				"tx_lane0_sync_clk",
				"rx_lane0_sync_clk",
				"rx_lane1_sync_clk";
			clocks =
				<&gcc GCC_UFS_PHY_AXI_CLK>,
				<&gcc GCC_AGGRE_UFS_PHY_AXI_CLK>,
				<&gcc GCC_UFS_PHY_AHB_CLK>,
				<&gcc GCC_UFS_PHY_UNIPRO_CORE_CLK>,
				<&rpmhcc RPMH_CXO_CLK>,
				<&gcc GCC_UFS_PHY_TX_SYMBOL_0_CLK>,
				<&gcc GCC_UFS_PHY_RX_SYMBOL_0_CLK>,
				<&gcc GCC_UFS_PHY_RX_SYMBOL_1_CLK>;
			freq-table-hz =
				<37500000 300000000>,
				<0 0>,
				<0 0>,
				<37500000 300000000>,
				<0 0>,
				<0 0>,
				<0 0>,
				<0 0>;

			status = "disabled";
		};

		ufs_mem_phy: phy@1d87000 {
			compatible = "qcom,sc8180x-qmp-ufs-phy";
			reg = <0 0x01d87000 0 0x1c0>;
			#address-cells = <2>;
			#size-cells = <2>;
			ranges;
			clock-names = "ref",
				      "ref_aux";
			clocks = <&rpmhcc RPMH_CXO_CLK>,
				 <&gcc GCC_UFS_PHY_PHY_AUX_CLK>;

			resets = <&ufs_mem_hc 0>;
			reset-names = "ufsphy";
			status = "disabled";

			ufs_mem_phy_lanes: lanes@1d87400 {
				reg = <0 0x01d87400 0 0x108>,
				      <0 0x01d87600 0 0x1e0>,
				      <0 0x01d87c00 0 0x1dc>,
				      <0 0x01d87800 0 0x108>,
				      <0 0x01d87a00 0 0x1e0>;
				#phy-cells = <0>;
			};
		};

		tcsr_mutex: hwlock@1f40000 {
			compatible = "qcom,tcsr-mutex";
			reg = <0x0 0x01f40000 0x0 0x40000>;
			#hwlock-cells = <1>;
		};

		tlmm: pinctrl@3100000 {
			compatible = "qcom,sc8180x-tlmm";
			reg = <0 0x03100000 0 0x300000>,
			      <0 0x03500000 0 0x700000>,
			      <0 0x03d00000 0 0x300000>;
			reg-names = "west", "east", "south";
			interrupts = <GIC_SPI 208 IRQ_TYPE_LEVEL_HIGH>;
			gpio-controller;
			#gpio-cells = <2>;
			interrupt-controller;
			#interrupt-cells = <2>;
			gpio-ranges = <&tlmm 0 0 190>;
			wakeup-parent = <&pdc>;
		};

		remoteproc_mpss: remoteproc@4080000 {
			compatible = "qcom,sc8180x-mpss-pas";
			reg = <0x0 0x04080000 0x0 0x4040>;

			interrupts-extended = <&intc GIC_SPI 266 IRQ_TYPE_EDGE_RISING>,
					      <&modem_smp2p_in 0 IRQ_TYPE_EDGE_RISING>,
					      <&modem_smp2p_in 1 IRQ_TYPE_EDGE_RISING>,
					      <&modem_smp2p_in 2 IRQ_TYPE_EDGE_RISING>,
					      <&modem_smp2p_in 3 IRQ_TYPE_EDGE_RISING>,
					      <&modem_smp2p_in 7 IRQ_TYPE_EDGE_RISING>;
			interrupt-names = "wdog", "fatal", "ready", "handover",
					  "stop-ack", "shutdown-ack";

			clocks = <&rpmhcc RPMH_CXO_CLK>;
			clock-names = "xo";

			power-domains = <&aoss_qmp AOSS_QMP_LS_MODEM>,
					<&rpmhpd SC8180X_CX>,
					<&rpmhpd SC8180X_MSS>;
			power-domain-names = "load_state", "cx", "mss";

			qcom,smem-states = <&modem_smp2p_out 0>;
			qcom,smem-state-names = "stop";

			glink-edge {
				interrupts = <GIC_SPI 449 IRQ_TYPE_EDGE_RISING>;
				label = "modem";
				qcom,remote-pid = <1>;
				mboxes = <&apss_shared 12>;
			};
		};

		remoteproc_cdsp: remoteproc@8300000 {
			compatible = "qcom,sc8180x-cdsp-pas";
			reg = <0x0 0x08300000 0x0 0x4040>;

			interrupts-extended = <&intc GIC_SPI 578 IRQ_TYPE_EDGE_RISING>,
					      <&cdsp_smp2p_in 0 IRQ_TYPE_EDGE_RISING>,
					      <&cdsp_smp2p_in 1 IRQ_TYPE_EDGE_RISING>,
					      <&cdsp_smp2p_in 2 IRQ_TYPE_EDGE_RISING>,
					      <&cdsp_smp2p_in 3 IRQ_TYPE_EDGE_RISING>;
			interrupt-names = "wdog", "fatal", "ready",
					  "handover", "stop-ack";

			clocks = <&rpmhcc RPMH_CXO_CLK>;
			clock-names = "xo";

			power-domains = <&aoss_qmp AOSS_QMP_LS_CDSP>,
					<&rpmhpd SC8180X_CX>;
			power-domain-names = "load_state", "cx";

			qcom,smem-states = <&cdsp_smp2p_out 0>;
			qcom,smem-state-names = "stop";

			status = "disabled";

			glink-edge {
				interrupts = <GIC_SPI 574 IRQ_TYPE_EDGE_RISING>;
				label = "cdsp";
				qcom,remote-pid = <5>;
				mboxes = <&apss_shared 4>;
			};
		};

		usb_prim_hsphy: phy@88e2000 {
			compatible = "qcom,sc8180x-usb-hs-phy",
				     "qcom,usb-snps-hs-7nm-phy";
			reg = <0 0x088e2000 0 0x400>;
			status = "disabled";
			#phy-cells = <0>;

			clocks = <&rpmhcc RPMH_CXO_CLK>;
			clock-names = "ref";

			resets = <&gcc GCC_QUSB2PHY_PRIM_BCR>;
		};

		usb_sec_hsphy: phy@88e3000 {
			compatible = "qcom,sc8180x-usb-hs-phy",
				     "qcom,usb-snps-hs-7nm-phy";
			reg = <0 0x088e3000 0 0x400>;
			status = "disabled";
			#phy-cells = <0>;

			clocks = <&rpmhcc RPMH_CXO_CLK>;
			clock-names = "ref";

			resets = <&gcc GCC_QUSB2PHY_SEC_BCR>;
		};

		usb_prim_qmpphy: phy@88e9000 {
			compatible = "qcom,sc8180x-qmp-usb3-phy";
			reg = <0 0x088e9000 0 0x18c>,
			      <0 0x088e8000 0 0x10>;
			reg-names = "reg-base", "dp_com";
			status = "disabled";
			#clock-cells = <1>;
			#address-cells = <2>;
			#size-cells = <2>;
			ranges;

			clocks = <&gcc GCC_USB3_PRIM_PHY_AUX_CLK>,
				 <&rpmhcc RPMH_CXO_CLK>,
				 <&gcc GCC_USB3_PRIM_CLKREF_CLK>,
				 <&gcc GCC_USB3_PRIM_PHY_COM_AUX_CLK>;
			clock-names = "aux", "ref_clk_src", "ref", "com_aux";

			resets = <&gcc GCC_USB3_DP_PHY_PRIM_SP0_BCR>,
				 <&gcc GCC_USB3_PHY_PRIM_SP0_BCR>;
			reset-names = "phy", "common";

			usb_prim_ssphy: lanes@88e9200 {
				reg = <0 0x088e9200 0 0x200>,
				      <0 0x088e9400 0 0x200>,
				      <0 0x088e9c00 0 0x218>,
				      <0 0x088e9600 0 0x200>,
				      <0 0x088e9800 0 0x200>,
				      <0 0x088e9a00 0 0x100>;
				#phy-cells = <0>;
				clocks = <&gcc GCC_USB3_PRIM_PHY_PIPE_CLK>;
				clock-names = "pipe0";
				clock-output-names = "usb3_prim_phy_pipe_clk_src";
			};
		};

		usb_sec_qmpphy: phy@88ee000 {
			compatible = "qcom,sc8180x-qmp-usb3-phy";
			reg = <0 0x088ee000 0 0x18c>,
			      <0 0x088ed000 0 0x10>;
			reg-names = "reg-base", "dp_com";
			status = "disabled";
			#clock-cells = <1>;
			#address-cells = <2>;
			#size-cells = <2>;
			ranges;

			clocks = <&gcc GCC_USB3_SEC_PHY_AUX_CLK>,
				 <&rpmhcc RPMH_CXO_CLK>,
				 <&gcc GCC_USB3_SEC_CLKREF_CLK>,
				 <&gcc GCC_USB3_SEC_PHY_COM_AUX_CLK>;
			clock-names = "aux", "ref_clk_src", "ref", "com_aux";

			resets = <&gcc GCC_USB3_DP_PHY_SEC_BCR>,
				 <&gcc GCC_USB3_PHY_SEC_BCR>;
			reset-names = "phy", "common";

			usb_sec_ssphy: lanes@88e9200 {
				reg = <0 0x088ee200 0 0x200>,
				      <0 0x088ee400 0 0x200>,
				      <0 0x088eec00 0 0x218>,
				      <0 0x088ee600 0 0x200>,
				      <0 0x088ee800 0 0x200>,
				      <0 0x088eea00 0 0x100>;
				#phy-cells = <0>;
				clocks = <&gcc GCC_USB3_SEC_PHY_PIPE_CLK>;
				clock-names = "pipe0";
				clock-output-names = "usb3_sec_phy_pipe_clk_src";
			};
		};

		usb_prim: usb@a6f8800 {
			compatible = "qcom,sc8180x-dwc3", "qcom,dwc3";
			reg = <0 0x0a6f8800 0 0x400>;
			status = "disabled";
			#address-cells = <2>;
			#size-cells = <2>;
			ranges;
			dma-ranges;

			clocks = <&gcc GCC_CFG_NOC_USB3_PRIM_AXI_CLK>,
				 <&gcc GCC_USB30_PRIM_MASTER_CLK>,
				 <&gcc GCC_AGGRE_USB3_PRIM_AXI_CLK>,
				 <&gcc GCC_USB30_PRIM_MOCK_UTMI_CLK>,
				 <&gcc GCC_USB30_PRIM_SLEEP_CLK>,
				 <&gcc GCC_USB3_SEC_CLKREF_CLK>;
			clock-names = "cfg_noc", "core", "iface", "mock_utmi",
				      "sleep", "xo";

			assigned-clocks = <&gcc GCC_USB30_PRIM_MOCK_UTMI_CLK>,
					  <&gcc GCC_USB30_PRIM_MASTER_CLK>;
			assigned-clock-rates = <19200000>, <200000000>;

			interrupts = <GIC_SPI 131 IRQ_TYPE_LEVEL_HIGH>,
				     <GIC_SPI 486 IRQ_TYPE_LEVEL_HIGH>,
				     <GIC_SPI 488 IRQ_TYPE_LEVEL_HIGH>,
				     <GIC_SPI 489 IRQ_TYPE_LEVEL_HIGH>;
			interrupt-names = "hs_phy_irq", "ss_phy_irq",
					  "dm_hs_phy_irq", "dp_hs_phy_irq";

			power-domains = <&gcc USB30_PRIM_GDSC>;

			resets = <&gcc GCC_USB30_PRIM_BCR>;

			usb_prim_dwc3: dwc3@a600000 {
				compatible = "snps,dwc3";
				reg = <0 0x0a600000 0 0xcd00>;
				interrupts = <GIC_SPI 133 IRQ_TYPE_LEVEL_HIGH>;
				iommus = <&apps_smmu 0x140 0>;
				snps,dis_u2_susphy_quirk;
				snps,dis_enblslpm_quirk;
				phys = <&usb_prim_hsphy>, <&usb_prim_ssphy>;
				phy-names = "usb2-phy", "usb3-phy";
			};
		};

		usb_sec: usb@a8f8800 {
			compatible = "qcom,sc8180x-dwc3", "qcom,dwc3";
			reg = <0 0x0a8f8800 0 0x400>;
			status = "disabled";
			#address-cells = <2>;
			#size-cells = <2>;
			ranges;
			dma-ranges;

			clocks = <&gcc GCC_CFG_NOC_USB3_SEC_AXI_CLK>,
				 <&gcc GCC_USB30_SEC_MASTER_CLK>,
				 <&gcc GCC_AGGRE_USB3_SEC_AXI_CLK>,
				 <&gcc GCC_USB30_SEC_MOCK_UTMI_CLK>,
				 <&gcc GCC_USB30_SEC_SLEEP_CLK>,
				 <&gcc GCC_USB3_SEC_CLKREF_CLK>;
			clock-names = "cfg_noc", "core", "iface", "mock_utmi",
				      "sleep", "xo";

			assigned-clocks = <&gcc GCC_USB30_SEC_MOCK_UTMI_CLK>,
					  <&gcc GCC_USB30_SEC_MASTER_CLK>;
			assigned-clock-rates = <19200000>, <200000000>;

			interrupts = <GIC_SPI 136 IRQ_TYPE_LEVEL_HIGH>,
				     <GIC_SPI 487 IRQ_TYPE_LEVEL_HIGH>,
				     <GIC_SPI 490 IRQ_TYPE_LEVEL_HIGH>,
				     <GIC_SPI 491 IRQ_TYPE_LEVEL_HIGH>;
			interrupt-names = "hs_phy_irq", "ss_phy_irq",
					  "dm_hs_phy_irq", "dp_hs_phy_irq";

			power-domains = <&gcc USB30_SEC_GDSC>;

			resets = <&gcc GCC_USB30_SEC_BCR>;

			usb_sec_dwc3: dwc3@a800000 {
				compatible = "snps,dwc3";
				reg = <0 0x0a800000 0 0xcd00>;
				interrupts = <GIC_SPI 138 IRQ_TYPE_LEVEL_HIGH>;
				iommus = <&apps_smmu 0x160 0>;
				snps,dis_u2_susphy_quirk;
				snps,dis_enblslpm_quirk;
				phys = <&usb_sec_hsphy>, <&usb_sec_ssphy>;
				phy-names = "usb2-phy", "usb3-phy";
			};
		};

		pdc: interrupt-controller@b220000 {
			compatible = "qcom,sc8180x-pdc", "qcom,pdc";
			reg = <0 0x0b220000 0 0x30000>;
			qcom,pdc-ranges = <0 480 94>, <94 609 31>;
			#interrupt-cells = <2>;
			interrupt-parent = <&intc>;
			interrupt-controller;
		};

		aoss_qmp: power-controller@c300000 {
			compatible = "qcom,sc8180x-aoss-qmp";
			reg = <0x0 0x0c300000 0x0 0x100000>;
			interrupts = <GIC_SPI 389 IRQ_TYPE_EDGE_RISING>;
			mboxes = <&apss_shared 0>;

			#clock-cells = <0>;
			#power-domain-cells = <1>;
		};

		apps_smmu: iommu@15000000 {
			compatible = "qcom,sc8180x-smmu-500", "arm,mmu-500";
			reg = <0 0x15000000 0 0x100000>;
			#iommu-cells = <2>;
			#global-interrupts = <1>;
			interrupts = <GIC_SPI 65 IRQ_TYPE_LEVEL_HIGH>,
				     <GIC_SPI 97 IRQ_TYPE_LEVEL_HIGH>,
				     <GIC_SPI 98 IRQ_TYPE_LEVEL_HIGH>,
				     <GIC_SPI 99 IRQ_TYPE_LEVEL_HIGH>,
				     <GIC_SPI 100 IRQ_TYPE_LEVEL_HIGH>,
				     <GIC_SPI 101 IRQ_TYPE_LEVEL_HIGH>,
				     <GIC_SPI 102 IRQ_TYPE_LEVEL_HIGH>,
				     <GIC_SPI 103 IRQ_TYPE_LEVEL_HIGH>,
				     <GIC_SPI 104 IRQ_TYPE_LEVEL_HIGH>,
				     <GIC_SPI 105 IRQ_TYPE_LEVEL_HIGH>,
				     <GIC_SPI 106 IRQ_TYPE_LEVEL_HIGH>,
				     <GIC_SPI 107 IRQ_TYPE_LEVEL_HIGH>,
				     <GIC_SPI 108 IRQ_TYPE_LEVEL_HIGH>,
				     <GIC_SPI 109 IRQ_TYPE_LEVEL_HIGH>,
				     <GIC_SPI 110 IRQ_TYPE_LEVEL_HIGH>,
				     <GIC_SPI 111 IRQ_TYPE_LEVEL_HIGH>,
				     <GIC_SPI 112 IRQ_TYPE_LEVEL_HIGH>,
				     <GIC_SPI 113 IRQ_TYPE_LEVEL_HIGH>,
				     <GIC_SPI 114 IRQ_TYPE_LEVEL_HIGH>,
				     <GIC_SPI 115 IRQ_TYPE_LEVEL_HIGH>,
				     <GIC_SPI 116 IRQ_TYPE_LEVEL_HIGH>,
				     <GIC_SPI 117 IRQ_TYPE_LEVEL_HIGH>,
				     <GIC_SPI 118 IRQ_TYPE_LEVEL_HIGH>,
				     <GIC_SPI 181 IRQ_TYPE_LEVEL_HIGH>,
				     <GIC_SPI 182 IRQ_TYPE_LEVEL_HIGH>,
				     <GIC_SPI 183 IRQ_TYPE_LEVEL_HIGH>,
				     <GIC_SPI 184 IRQ_TYPE_LEVEL_HIGH>,
				     <GIC_SPI 185 IRQ_TYPE_LEVEL_HIGH>,
				     <GIC_SPI 186 IRQ_TYPE_LEVEL_HIGH>,
				     <GIC_SPI 187 IRQ_TYPE_LEVEL_HIGH>,
				     <GIC_SPI 188 IRQ_TYPE_LEVEL_HIGH>,
				     <GIC_SPI 189 IRQ_TYPE_LEVEL_HIGH>,
				     <GIC_SPI 190 IRQ_TYPE_LEVEL_HIGH>,
				     <GIC_SPI 191 IRQ_TYPE_LEVEL_HIGH>,
				     <GIC_SPI 192 IRQ_TYPE_LEVEL_HIGH>,
				     <GIC_SPI 315 IRQ_TYPE_LEVEL_HIGH>,
				     <GIC_SPI 316 IRQ_TYPE_LEVEL_HIGH>,
				     <GIC_SPI 317 IRQ_TYPE_LEVEL_HIGH>,
				     <GIC_SPI 318 IRQ_TYPE_LEVEL_HIGH>,
				     <GIC_SPI 319 IRQ_TYPE_LEVEL_HIGH>,
				     <GIC_SPI 320 IRQ_TYPE_LEVEL_HIGH>,
				     <GIC_SPI 321 IRQ_TYPE_LEVEL_HIGH>,
				     <GIC_SPI 322 IRQ_TYPE_LEVEL_HIGH>,
				     <GIC_SPI 323 IRQ_TYPE_LEVEL_HIGH>,
				     <GIC_SPI 324 IRQ_TYPE_LEVEL_HIGH>,
				     <GIC_SPI 325 IRQ_TYPE_LEVEL_HIGH>,
				     <GIC_SPI 326 IRQ_TYPE_LEVEL_HIGH>,
				     <GIC_SPI 327 IRQ_TYPE_LEVEL_HIGH>,
				     <GIC_SPI 328 IRQ_TYPE_LEVEL_HIGH>,
				     <GIC_SPI 329 IRQ_TYPE_LEVEL_HIGH>,
				     <GIC_SPI 330 IRQ_TYPE_LEVEL_HIGH>,
				     <GIC_SPI 331 IRQ_TYPE_LEVEL_HIGH>,
				     <GIC_SPI 332 IRQ_TYPE_LEVEL_HIGH>,
				     <GIC_SPI 333 IRQ_TYPE_LEVEL_HIGH>,
				     <GIC_SPI 334 IRQ_TYPE_LEVEL_HIGH>,
				     <GIC_SPI 335 IRQ_TYPE_LEVEL_HIGH>,
				     <GIC_SPI 336 IRQ_TYPE_LEVEL_HIGH>,
				     <GIC_SPI 337 IRQ_TYPE_LEVEL_HIGH>,
				     <GIC_SPI 338 IRQ_TYPE_LEVEL_HIGH>,
				     <GIC_SPI 339 IRQ_TYPE_LEVEL_HIGH>,
				     <GIC_SPI 340 IRQ_TYPE_LEVEL_HIGH>,
				     <GIC_SPI 341 IRQ_TYPE_LEVEL_HIGH>,
				     <GIC_SPI 342 IRQ_TYPE_LEVEL_HIGH>,
				     <GIC_SPI 343 IRQ_TYPE_LEVEL_HIGH>,
				     <GIC_SPI 344 IRQ_TYPE_LEVEL_HIGH>,
				     <GIC_SPI 345 IRQ_TYPE_LEVEL_HIGH>,
				     <GIC_SPI 395 IRQ_TYPE_LEVEL_HIGH>,
				     <GIC_SPI 396 IRQ_TYPE_LEVEL_HIGH>,
				     <GIC_SPI 397 IRQ_TYPE_LEVEL_HIGH>,
				     <GIC_SPI 398 IRQ_TYPE_LEVEL_HIGH>,
				     <GIC_SPI 399 IRQ_TYPE_LEVEL_HIGH>,
				     <GIC_SPI 400 IRQ_TYPE_LEVEL_HIGH>,
				     <GIC_SPI 401 IRQ_TYPE_LEVEL_HIGH>,
				     <GIC_SPI 402 IRQ_TYPE_LEVEL_HIGH>,
				     <GIC_SPI 403 IRQ_TYPE_LEVEL_HIGH>,
				     <GIC_SPI 404 IRQ_TYPE_LEVEL_HIGH>,
				     <GIC_SPI 405 IRQ_TYPE_LEVEL_HIGH>,
				     <GIC_SPI 406 IRQ_TYPE_LEVEL_HIGH>,
				     <GIC_SPI 407 IRQ_TYPE_LEVEL_HIGH>,
				     <GIC_SPI 408 IRQ_TYPE_LEVEL_HIGH>,
				     <GIC_SPI 409 IRQ_TYPE_LEVEL_HIGH>,
				     <GIC_SPI 410 IRQ_TYPE_LEVEL_HIGH>,
				     <GIC_SPI 411 IRQ_TYPE_LEVEL_HIGH>,
				     <GIC_SPI 412 IRQ_TYPE_LEVEL_HIGH>,
				     <GIC_SPI 413 IRQ_TYPE_LEVEL_HIGH>,
				     <GIC_SPI 706 IRQ_TYPE_LEVEL_HIGH>,
				     <GIC_SPI 707 IRQ_TYPE_LEVEL_HIGH>,
				     <GIC_SPI 708 IRQ_TYPE_LEVEL_HIGH>,
				     <GIC_SPI 709 IRQ_TYPE_LEVEL_HIGH>,
				     <GIC_SPI 710 IRQ_TYPE_LEVEL_HIGH>,
				     <GIC_SPI 711 IRQ_TYPE_LEVEL_HIGH>,
				     <GIC_SPI 712 IRQ_TYPE_LEVEL_HIGH>,
				     <GIC_SPI 713 IRQ_TYPE_LEVEL_HIGH>,
				     <GIC_SPI 714 IRQ_TYPE_LEVEL_HIGH>,
				     <GIC_SPI 715 IRQ_TYPE_LEVEL_HIGH>,
				     <GIC_SPI 643 IRQ_TYPE_LEVEL_HIGH>,
				     <GIC_SPI 642 IRQ_TYPE_LEVEL_HIGH>,
				     <GIC_SPI 641 IRQ_TYPE_LEVEL_HIGH>,
				     <GIC_SPI 640 IRQ_TYPE_LEVEL_HIGH>,
				     <GIC_SPI 768 IRQ_TYPE_LEVEL_HIGH>,
				     <GIC_SPI 769 IRQ_TYPE_LEVEL_HIGH>,
				     <GIC_SPI 770 IRQ_TYPE_LEVEL_HIGH>,
				     <GIC_SPI 771 IRQ_TYPE_LEVEL_HIGH>,
				     <GIC_SPI 772 IRQ_TYPE_LEVEL_HIGH>,
				     <GIC_SPI 773 IRQ_TYPE_LEVEL_HIGH>,
				     <GIC_SPI 774 IRQ_TYPE_LEVEL_HIGH>,
				     <GIC_SPI 775 IRQ_TYPE_LEVEL_HIGH>;

		};

		remoteproc_adsp: remoteproc@17300000 {
			compatible = "qcom,sc8180x-adsp-pas";
			reg = <0x0 0x17300000 0x0 0x4040>;

			interrupts-extended = <&intc GIC_SPI 162 IRQ_TYPE_EDGE_RISING>,
					      <&adsp_smp2p_in 0 IRQ_TYPE_EDGE_RISING>,
					      <&adsp_smp2p_in 1 IRQ_TYPE_EDGE_RISING>,
					      <&adsp_smp2p_in 2 IRQ_TYPE_EDGE_RISING>,
					      <&adsp_smp2p_in 3 IRQ_TYPE_EDGE_RISING>;
			interrupt-names = "wdog", "fatal", "ready",
					  "handover", "stop-ack";

			clocks = <&rpmhcc RPMH_CXO_CLK>;
			clock-names = "xo";

			power-domains = <&aoss_qmp AOSS_QMP_LS_LPASS>,
					<&rpmhpd SC8180X_CX>;
			power-domain-names = "load_state", "cx";

			qcom,smem-states = <&adsp_smp2p_out 0>;
			qcom,smem-state-names = "stop";

			status = "disabled";

			glink-edge {
				interrupts = <GIC_SPI 156 IRQ_TYPE_EDGE_RISING>;
				label = "lpass";
				qcom,remote-pid = <2>;
				mboxes = <&apss_shared 8>;
			};
		};

		intc: interrupt-controller@17a00000 {
			compatible = "arm,gic-v3";
			interrupt-controller;
			#interrupt-cells = <3>;
			reg = <0x0 0x17a00000 0x0 0x10000>,	/* GICD */
			      <0x0 0x17a60000 0x0 0x100000>;	/* GICR * 8 */
			interrupts = <GIC_PPI 9 IRQ_TYPE_LEVEL_HIGH>;
		};

		apss_shared: mailbox@17c00000 {
			compatible = "qcom,sc8180x-apss-shared";
			reg = <0x0 0x17c00000 0x0 0x1000>;
			#mbox-cells = <1>;
		};

		timer@17c20000 {
			#address-cells = <2>;
			#size-cells = <2>;
			ranges;
			compatible = "arm,armv7-timer-mem";
			reg = <0x0 0x17c20000 0x0 0x1000>;
			clock-frequency = <19200000>;

			frame@17c21000{
				frame-number = <0>;
				interrupts = <GIC_SPI 8 IRQ_TYPE_LEVEL_HIGH>,
					     <GIC_SPI 6 IRQ_TYPE_LEVEL_HIGH>;
				reg = <0x0 0x17c21000 0x0 0x1000>,
				      <0x0 0x17c22000 0x0 0x1000>;
			};

			frame@17c23000 {
				frame-number = <1>;
				interrupts = <GIC_SPI 9 IRQ_TYPE_LEVEL_HIGH>;
				reg = <0x0 0x17c23000 0x0 0x1000>;
				status = "disabled";
			};

			frame@17c25000 {
				frame-number = <2>;
				interrupts = <GIC_SPI 10 IRQ_TYPE_LEVEL_HIGH>;
				reg = <0x0 0x17c25000 0x0 0x1000>;
				status = "disabled";
			};

			frame@17c27000 {
				frame-number = <3>;
				interrupts = <GIC_SPI 11 IRQ_TYPE_LEVEL_HIGH>;
				reg = <0x0 0x17c26000 0x0 0x1000>;
				status = "disabled";
			};

			frame@17c29000 {
				frame-number = <4>;
				interrupts = <GIC_SPI 12 IRQ_TYPE_LEVEL_HIGH>;
				reg = <0x0 0x17c29000 0x0 0x1000>;
				status = "disabled";
			};

			frame@17c2b000 {
				frame-number = <5>;
				interrupts = <GIC_SPI 13 IRQ_TYPE_LEVEL_HIGH>;
				reg = <0x0 0x17c2b000 0x0 0x1000>;
				status = "disabled";
			};

			frame@17c2d000 {
				frame-number = <6>;
				interrupts = <GIC_SPI 14 IRQ_TYPE_LEVEL_HIGH>;
				reg = <0x0 0x17c2d000 0x0 0x1000>;
				status = "disabled";
			};
		};

		apps_rsc: rsc@18200000 {
			label = "apps_rsc";
			compatible = "qcom,rpmh-rsc";
			reg = <0x0 0x18200000 0x0 0x10000>,
			      <0x0 0x18210000 0x0 0x10000>,
			      <0x0 0x18220000 0x0 0x10000>;
			reg-names = "drv-0", "drv-1", "drv-2";
			interrupts = <GIC_SPI 3 IRQ_TYPE_LEVEL_HIGH>,
				     <GIC_SPI 4 IRQ_TYPE_LEVEL_HIGH>,
				     <GIC_SPI 5 IRQ_TYPE_LEVEL_HIGH>;
			qcom,tcs-offset = <0xd00>;
			qcom,drv-id = <2>;
			qcom,tcs-config = <ACTIVE_TCS  2>,
					  <SLEEP_TCS   1>,
					  <WAKE_TCS    1>,
					  <CONTROL_TCS 0>;

			rpmhcc: clock-controller {
				compatible = "qcom,sc8180x-rpmh-clk";
				#clock-cells = <1>;
				clock-names = "xo";
				clocks = <&xo_board>;
			};

			rpmhpd: power-controller {
				compatible = "qcom,sc8180x-rpmhpd";
				#power-domain-cells = <1>;
				operating-points-v2 = <&rpmhpd_opp_table>;

				rpmhpd_opp_table: opp-table {
					compatible = "operating-points-v2";

					rpmhpd_opp_ret: opp1 {
						opp-level = <RPMH_REGULATOR_LEVEL_RETENTION>;
					};

					rpmhpd_opp_min_svs: opp2 {
						opp-level = <RPMH_REGULATOR_LEVEL_MIN_SVS>;
					};

					rpmhpd_opp_low_svs: opp3 {
						opp-level = <RPMH_REGULATOR_LEVEL_LOW_SVS>;
					};

					rpmhpd_opp_svs: opp4 {
						opp-level = <RPMH_REGULATOR_LEVEL_SVS>;
					};

					rpmhpd_opp_svs_l1: opp5 {
						opp-level = <RPMH_REGULATOR_LEVEL_SVS_L1>;
					};

					rpmhpd_opp_nom: opp6 {
						opp-level = <RPMH_REGULATOR_LEVEL_NOM>;
					};

					rpmhpd_opp_nom_l1: opp7 {
						opp-level = <RPMH_REGULATOR_LEVEL_NOM_L1>;
					};

					rpmhpd_opp_nom_l2: opp8 {
						opp-level = <RPMH_REGULATOR_LEVEL_NOM_L2>;
					};

					rpmhpd_opp_turbo: opp9 {
						opp-level = <RPMH_REGULATOR_LEVEL_TURBO>;
					};

					rpmhpd_opp_turbo_l1: opp10 {
						opp-level = <RPMH_REGULATOR_LEVEL_TURBO_L1>;
					};
				};
			};
		};

		cpufreq_hw: cpufreq@18323000 {
			compatible = "qcom,cpufreq-hw";
			reg = <0 0x18323000 0 0x1400>, <0 0x18325800 0 0x1400>;
			reg-names = "freq-domain0", "freq-domain1";

			clocks = <&rpmhcc RPMH_CXO_CLK>, <&gcc GPLL0>;
			clock-names = "xo", "alternate";

			#freq-domain-cells = <1>;
		};

		wifi: wifi@18800000 {
			compatible = "qcom,wcn3990-wifi";
			reg = <0 0x18800000 0 0x800000>;
			reg-names = "membase";
			clock-names = "cxo_ref_clk_pin";
			clocks = <&rpmhcc RPMH_RF_CLK2>;
			interrupts = <GIC_SPI 414 IRQ_TYPE_LEVEL_HIGH>,
				     <GIC_SPI 415 IRQ_TYPE_LEVEL_HIGH>,
				     <GIC_SPI 416 IRQ_TYPE_LEVEL_HIGH>,
				     <GIC_SPI 417 IRQ_TYPE_LEVEL_HIGH>,
				     <GIC_SPI 418 IRQ_TYPE_LEVEL_HIGH>,
				     <GIC_SPI 419 IRQ_TYPE_LEVEL_HIGH>,
				     <GIC_SPI 420 IRQ_TYPE_LEVEL_HIGH>,
				     <GIC_SPI 421 IRQ_TYPE_LEVEL_HIGH>,
				     <GIC_SPI 422 IRQ_TYPE_LEVEL_HIGH>,
				     <GIC_SPI 423 IRQ_TYPE_LEVEL_HIGH>,
				     <GIC_SPI 424 IRQ_TYPE_LEVEL_HIGH>,
				     <GIC_SPI 425 IRQ_TYPE_LEVEL_HIGH>;
			iommus = <&apps_smmu 0x0640 0x1>;
			qcom,msa-fixed-perm;
			status = "disabled";
		};
	};

	timer {
		compatible = "arm,armv8-timer";
		interrupts = <GIC_PPI 1 IRQ_TYPE_LEVEL_LOW>,
			     <GIC_PPI 2 IRQ_TYPE_LEVEL_LOW>,
			     <GIC_PPI 3 IRQ_TYPE_LEVEL_LOW>,
			     <GIC_PPI 0 IRQ_TYPE_LEVEL_LOW>;
	};
};
